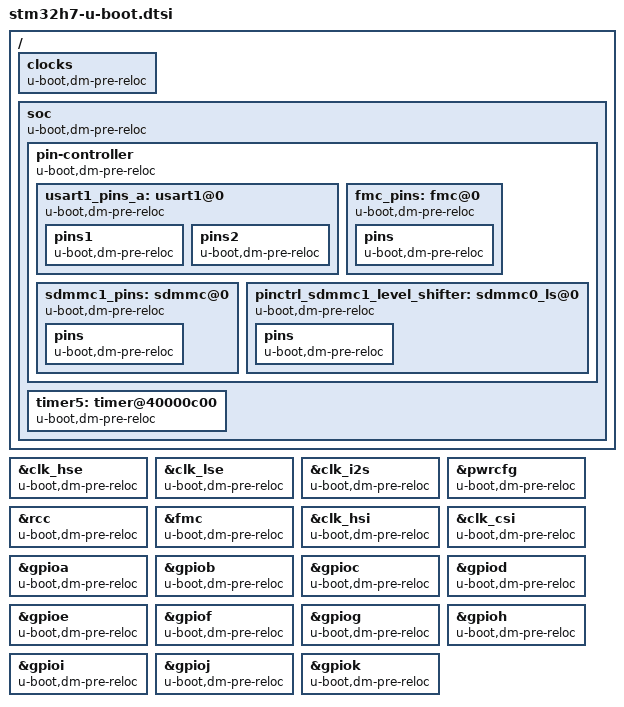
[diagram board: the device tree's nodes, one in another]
/{
	clocks {
		u-boot,dm-pre-reloc;
	};

	soc {
		u-boot,dm-pre-reloc;
		pin-controller {
				u-boot,dm-pre-reloc;
			usart1_pins_a: usart1@0	{
			u-boot,dm-pre-reloc;
				pins1 {
					u-boot,dm-pre-reloc;
					};
				pins2 {
					u-boot,dm-pre-reloc;
					};
						};
			fmc_pins: fmc@0 {
					u-boot,dm-pre-reloc;
				pins {
					u-boot,dm-pre-reloc;
				     };
					};
			sdmmc1_pins: sdmmc@0 {
					u-boot,dm-pre-reloc;
				pins {
					u-boot,dm-pre-reloc;
				     };
					     };
			pinctrl_sdmmc1_level_shifter: sdmmc0_ls@0 {
					u-boot,dm-pre-reloc;
				pins {
					u-boot,dm-pre-reloc;
				     };
					     };
				};

		timer5: timer@40000c00 {
			u-boot,dm-pre-reloc;
			};
	};
};
&clk_hse {
	u-boot,dm-pre-reloc;
};

&clk_lse {
	u-boot,dm-pre-reloc;
};

&clk_i2s {
	u-boot,dm-pre-reloc;
};

&pwrcfg {
	u-boot,dm-pre-reloc;
};

&rcc {
	u-boot,dm-pre-reloc;
};

&fmc {
	u-boot,dm-pre-reloc;
};

&clk_hsi {
	u-boot,dm-pre-reloc;
};

&clk_csi {
	u-boot,dm-pre-reloc;
};

&gpioa {
	u-boot,dm-pre-reloc;
};

&gpiob {
	u-boot,dm-pre-reloc;
};

&gpioc {
	u-boot,dm-pre-reloc;
};

&gpiod {
	u-boot,dm-pre-reloc;
};

&gpioe {
	u-boot,dm-pre-reloc;
};

&gpiof {
	u-boot,dm-pre-reloc;
};

&gpiog {
	u-boot,dm-pre-reloc;
};

&gpioh {
	u-boot,dm-pre-reloc;
};

&gpioi {
	u-boot,dm-pre-reloc;
};

&gpioj {
	u-boot,dm-pre-reloc;
};

&gpiok {
	u-boot,dm-pre-reloc;
};
